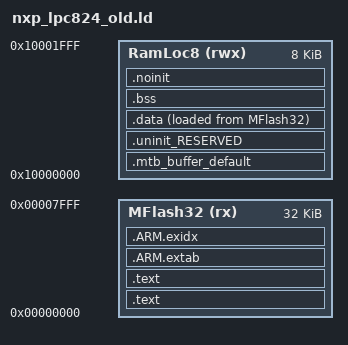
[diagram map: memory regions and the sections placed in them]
/*
 * GENERATED FILE - DO NOT EDIT
 * (c) Code Red Technologies Ltd, 2008-2013
 * (c) NXP Semiconductors 2013-2018
 * Generated linker script file for LPC824
 * Created from linkscript.ldt by FMCreateLinkLibraries
 * Using Freemarker v2.3.23
 * MCUXpresso IDE v10.2.1 [Build 795] [2018-07-25] on Oct 18, 2018 10:26:25 PM
 */

GROUP (
  "libgcc.a"
  "libc.a"
  "libstdc++.a"
  "libm.a"
  /*"libcr_newlib_nohost.a"*/
  "crti.o"
  "crtn.o"
  "crtbegin.o"
  "crtend.o"
)

MEMORY
{
  /* Define each memory region */
  MFlash32 (rx) : ORIGIN = 0x0, LENGTH = 0x8000 /* 32K bytes (alias Flash) */  
  RamLoc8 (rwx) : ORIGIN = 0x10000000, LENGTH = 0x2000 /* 8K bytes (alias RAM) */  
}

  /* Define a symbol for the top of each memory region */
  __base_MFlash32 = 0x0  ; /* MFlash32 */  
  __base_Flash = 0x0 ; /* Flash */  
  __top_MFlash32 = 0x0 + 0x8000 ; /* 32K bytes */  
  __top_Flash = 0x0 + 0x8000 ; /* 32K bytes */  
  __base_RamLoc8 = 0x10000000  ; /* RamLoc8 */  
  __base_RAM = 0x10000000 ; /* RAM */  
  __top_RamLoc8 = 0x10000000 + 0x2000 ; /* 8K bytes */  
  __top_RAM = 0x10000000 + 0x2000 ; /* 8K bytes */  

ENTRY(Reset_Handler)

SECTIONS
{
    /* MAIN TEXT SECTION */
    .text : ALIGN(4)
    {
        FILL(0xff)
        __vectors_start__ = ABSOLUTE(.) ;
        KEEP(*(.isr_vector))
        /* Global Section Table */
        . = ALIGN(4) ;
        __section_table_start = .;
        __data_section_table = .;
        LONG(LOADADDR(.data));
        LONG(    ADDR(.data));
        LONG(  SIZEOF(.data));
        __data_section_table_end = .;
        __bss_section_table = .;
        LONG(    ADDR(.bss));
        LONG(  SIZEOF(.bss));
        __bss_section_table_end = .;
        __section_table_end = . ;
        _end_text = . ;
        /* End of Global Section Table */

        *(.after_vectors*)

    } > MFlash32

    .text : ALIGN(4)
    {
       *(.text*)
       *(.rodata .rodata.* .constdata .constdata.*)
       . = ALIGN(4);
            /* C++ constructors etc */
            . = ALIGN(4);
            KEEP(*(.init))
            
            . = ALIGN(4);
            __preinit_array_start = .;
            KEEP (*(.preinit_array))
            __preinit_array_end = .;
            
            . = ALIGN(4);
            __init_array_start = .;
            KEEP (*(SORT(.init_array.*)))
            KEEP (*(.init_array))
            __init_array_end = .;
            
            KEEP(*(.fini));
            
            . = ALIGN(4);
            KEEP (*crtbegin.o(.ctors))
            KEEP (*(EXCLUDE_FILE (*crtend.o) .ctors))
            KEEP (*(SORT(.ctors.*)))
            KEEP (*crtend.o(.ctors))
            
            . = ALIGN(4);
            KEEP (*crtbegin.o(.dtors))
            KEEP (*(EXCLUDE_FILE (*crtend.o) .dtors))
            KEEP (*(SORT(.dtors.*)))
            KEEP (*crtend.o(.dtors))
            . = ALIGN(4);
            /* End C++ */
    } > MFlash32
    /*
     * for exception handling/unwind - some Newlib functions (in common
     * with C++ and STDC++) use this. 
     */
    .ARM.extab : ALIGN(4) 
    {
        *(.ARM.extab* .gnu.linkonce.armextab.*)
    } > MFlash32

    __exidx_start = .;

    .ARM.exidx : ALIGN(4)
    {
        *(.ARM.exidx* .gnu.linkonce.armexidx.*)
    } > MFlash32
    __exidx_end = .;

    _etext = .;
        
    /* MAIN DATA SECTION */
        /* Default MTB section */
        .mtb_buffer_default (NOLOAD) :
        {
           KEEP(*(.mtb*))
        } > RamLoc8
    .uninit_RESERVED : ALIGN(4)
    {
        KEEP(*(.bss.$RESERVED*))
        . = ALIGN(4) ;
        _end_uninit_RESERVED = .;
    } > RamLoc8

    /* Main DATA section (RamLoc8) */
    .data : ALIGN(4)
    {
       FILL(0xff)
       _start_data = . ;
       *(vtable)
       *(.ramfunc*)
       *(.data*)
       . = ALIGN(4) ;
       _end_data = . ;
    } > RamLoc8 AT>MFlash32

    /* MAIN BSS SECTION */
    .bss : ALIGN(4)
    {
        _start_bss = .;
        *(.bss*)
        *(COMMON)
        . = ALIGN(4) ;
        _end_bss = .;
        PROVIDE(end = .);
    } > RamLoc8

    /* DEFAULT NOINIT SECTION */
    .noinit (NOLOAD): ALIGN(4)
    {
        _noinit = .;
        *(.noinit*) 
         . = ALIGN(4) ;
        _end_noinit = .;
    } > RamLoc8
    PROVIDE(_pvHeapStart = DEFINED(__user_heap_base) ? __user_heap_base : .);
    PROVIDE(_vStackTop = DEFINED(__user_stack_top) ? __user_stack_top : __top_RamLoc8 - 0);

    /* ## Create checksum value (used in startup) ## */
    PROVIDE(__valid_user_code_checksum = 0 - 
                                         (_vStackTop 
                                         + (Reset_Handler + 1) 
                                         + (( DEFINED(NMI_Handler) ? NMI_Handler : M0_NMI_Handler ) + 1) 
                                         + (( DEFINED(HardFault_Handler) ? HardFault_Handler : M0_HardFault_Handler ) + 1) 
                                         )
           );

    /* Provide basic symbols giving location and size of main text
     * block, including initial values of RW data sections. Note that
     * these will need extending to give a complete picture with
     * complex images (e.g multiple Flash banks).
     */
    _image_start = LOADADDR(.text);
    _image_end = LOADADDR(.data) + SIZEOF(.data);
    _image_size = _image_end - _image_start;
}
